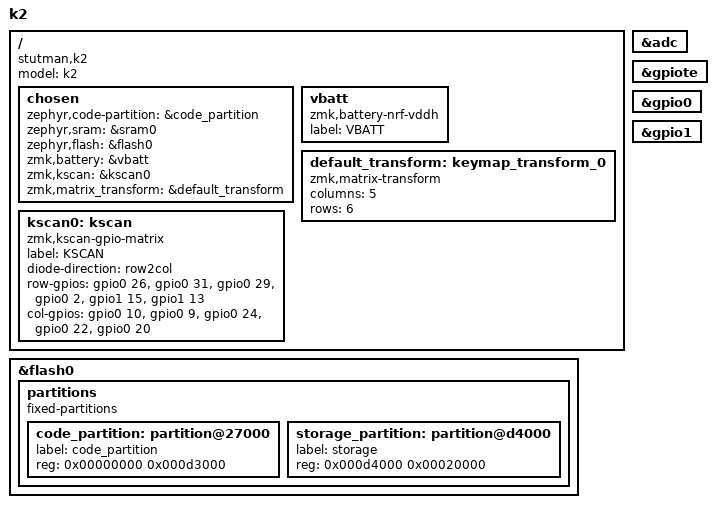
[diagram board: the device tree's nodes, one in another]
/*
 * Copyright (c) 2021 Dan Stutman
 *
 * SPDX-License-Identifier: MIT
 */

/dts-v1/;
#include <nordic/nrf52840_qiaa.dtsi>
#include <dt-bindings/zmk/matrix_transform.h>

/ {
	model = "k2";
	compatible = "stutman,k2";

	chosen {
		zephyr,code-partition = &code_partition;
		zephyr,sram = &sram0;
		zephyr,flash = &flash0;
      	zmk,battery = &vbatt;
		zmk,kscan = &kscan0;
		zmk,matrix_transform = &default_transform;
	};

    vbatt: vbatt {
        compatible = "zmk,battery-nrf-vddh";
        label = "VBATT";
    };

	default_transform: keymap_transform_0 {
		compatible = "zmk,matrix-transform";
		columns = <5>;
		rows = <6>;
	};

	kscan0: kscan {
		compatible = "zmk,kscan-gpio-matrix";
		label = "KSCAN";

		diode-direction = "row2col";
		row-gpios
			= <&gpio0 26 GPIO_ACTIVE_HIGH>
			, <&gpio0 31 GPIO_ACTIVE_HIGH>
			, <&gpio0 29 GPIO_ACTIVE_HIGH>
			, <&gpio0  2 GPIO_ACTIVE_HIGH>
			, <&gpio1 15 GPIO_ACTIVE_HIGH>
			, <&gpio1 13 GPIO_ACTIVE_HIGH>
			;
		col-gpios
			= <&gpio0 10 (GPIO_ACTIVE_HIGH | GPIO_PULL_DOWN)>
			, <&gpio0  9 (GPIO_ACTIVE_HIGH | GPIO_PULL_DOWN)>
			, <&gpio0 24 (GPIO_ACTIVE_HIGH | GPIO_PULL_DOWN)>
			, <&gpio0 22 (GPIO_ACTIVE_HIGH | GPIO_PULL_DOWN)>
			, <&gpio0 20 (GPIO_ACTIVE_HIGH | GPIO_PULL_DOWN)>
			;
	};

	//leds {
	//	compatible = "gpio-leds";
	//	blue_led: led_0 {
	//		gpios = <&gpio0 4 GPIO_ACTIVE_HIGH>;
	//		label = "Blue LED";
	//	};
	//	red_led: led_1 {
	//		gpios = <&gpio0 6 GPIO_ACTIVE_HIGH>;
	//		label = "Red LED";
	//	};
	//};

//	vbatt {
//		compatible = "zmk,battery-voltage-divider";
//		label = "BATTERY";
//		io-channels = <&adc 2>;
//		output-ohms = <2000000>;
//		full-ohms = <(2000000 + 806000)>;
//	};
};

&adc {
	status = "okay";
};

&gpiote {
	status = "okay";
};

&gpio0 {
	status = "okay";
};

&gpio1 {
	status = "okay";
};

&flash0 {
	/*
	 * For more information, see:
	 * http://docs.zephyrproject.org/latest/devices/dts/flash_partitions.html
	 */
	partitions {
		compatible = "fixed-partitions";
		#address-cells = <1>;
		#size-cells = <1>;

		code_partition: partition@27000 {
			label = "code_partition";
			reg = <0x00000000 0x000d3000>;
		};

		/*
		 * The flash starting at 0x000d4000 and ending at
		 * 0x000f3fff is reserved for use by the application.
		 */

		/*
		 * Storage partition will be used by FCB/LittleFS/NVS
		 * if enabled.
		 */
		storage_partition: partition@d4000 {
			label = "storage";
			reg = <0x000d4000 0x00020000>;
		};
	};
};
